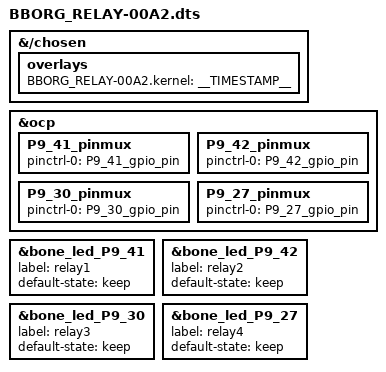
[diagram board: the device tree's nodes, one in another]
// SPDX-License-Identifier: GPL-2.0-only
/*
 * Copyright (C) 2015 Robert Nelson <robertcnelson@gmail.com>
 * Copyright (C) 2019 Amilcar Lucas <amilcar.lucas@iav.de>
 */

/dts-v1/;
/plugin/;

&{/chosen} {
	overlays {
		BBORG_RELAY-00A2.kernel = __TIMESTAMP__;
	};
};

&ocp {
	P9_41_pinmux { pinctrl-0 = <&P9_41_gpio_pin>;};
	P9_42_pinmux { pinctrl-0 = <&P9_42_gpio_pin>;};
	P9_30_pinmux { pinctrl-0 = <&P9_30_gpio_pin>;};
	P9_27_pinmux { pinctrl-0 = <&P9_27_gpio_pin>;};
};

// relay1
&bone_led_P9_41 {
	status = "okay";
	label = "relay1";
	default-state = "keep";
};

// relay2
&bone_led_P9_42 {
	status = "okay";
	label = "relay2";
	default-state = "keep";
};

// realy3
&bone_led_P9_30 {
	status = "okay";
	label = "relay3";
	default-state = "keep";
};

// realy4
&bone_led_P9_27 {
	status = "okay";
	label = "relay4";
	default-state = "keep";
};
